VERSION "WUFR 23.1.0"

BS_: 1000000 : 0,0

BU_: FLSB DAQ FRSB RSB

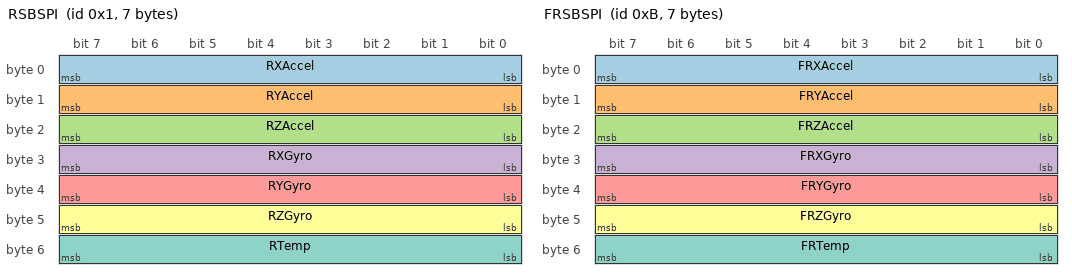
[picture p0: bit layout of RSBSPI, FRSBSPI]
BO_ 1 RSBSPI: 7 RSB
 SG_ RXAccel : 0|8@1- (0.307451,0.153725) [-39.2|39.2] "m/s^2" DAQ
 SG_ RYAccel : 8|8@1- (0.307451,0.153725) [-39.2|39.2] "m/s^2" DAQ
 SG_ RZAccel : 16|8@1- (0.307451,0.153725) [-39.2|39.2] "m/s^2" DAQ
 SG_ RXGyro : 24|8@1+ (1,0) [-80|80] "rad/s" DAQ
 SG_ RYGyro : 32|8@1+ (1,0) [-80|80] "rad/s" DAQ
 SG_ RZGyro : 40|8@1+ (1,0) [-80|80] "rad/s" DAQ
 SG_ RTemp : 48|8@1- (1,0) [-80|80] "rad/s" DAQ

BO_ 2 RSBAnlg1: 8 RSB
 SG_ RAnlg1 : 0|16@1+ (0.001,0) [0|5] "V" DAQ
 SG_ RAnlg2 : 16|32@1+ (0.001,0) [0|5] "V" DAQ
 SG_ RBrkPrs : 32|48@1+ (0.25,-125) [0|1000] "PSI" DAQ
 SG_ RAnlg4 : 48|64@1+ (0.001,0) [0|5] "V" DAQ

BO_ 3 RSBAnlg2: 4 RSB
 SG_ RAnlg5 : 0|16@1+ (0.001,0) [0|5] "V" DAQ
 SG_ RAnlg6 : 16|32@1+ (0.001,0) [0|5] "V" DAQ

BO_ 11 FRSBSPI: 7 FRSB
 SG_ FRXAccel : 0|8@1- (0.307451,0.153725) [-39.2|39.2] "m/s^2" DAQ
 SG_ FRYAccel : 8|8@1- (0.307451,0.153725) [-39.2|39.2] "m/s^2" DAQ
 SG_ FRZAccel : 16|8@1- (0.307451,0.153725) [-39.2|39.2] "m/s^2" DAQ
 SG_ FRXGyro : 24|8@1+ (1,0) [-80|80] "rad/s" DAQ
 SG_ FRYGyro : 32|8@1+ (1,0) [-80|80] "rad/s" DAQ
 SG_ FRZGyro : 40|8@1+ (1,0) [-80|80] "rad/s" DAQ
 SG_ FRTemp : 48|8@1- (1,0) [-80|80] "rad/s" DAQ

BO_ 12 FRSBAnlg1: 8 FRSB
 SG_ RadIn1 : 0|16@1+ (-0.13101462,375.7208) [-279.3523|375.7208] "F" DAQ
 SG_ RadIn2 : 16|32@1+ (-0.13101462,375.7208) [-279.3523|375.7208] "F" DAQ
 SG_ RadOut : 32|48@1+ (-0.13101462,375.7208) [-279.3523|375.7208] "F" DAQ
 SG_ FRAnlg4 : 48|64@1+ (0.001,0) [0|5] "V" DAQ

BO_ 13 FRSBAnlg2: 4 FRSB
 SG_ Pitot : 0|16@1+ (0.000045,-0.0225) [-0.0225|2.025] "PSI" DAQ
 SG_ FRAnlg6 : 16|32@1+ (0.001,0) [0|5] "V" DAQ

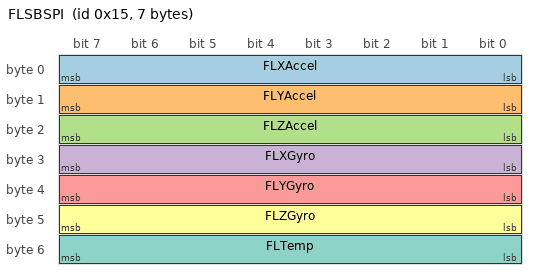
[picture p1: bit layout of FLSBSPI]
BO_ 21 FLSBSPI: 7 FLSB
 SG_ FLXAccel : 0|8@1- (0.307451,0.153725) [-39.2|39.2] "m/s^2" DAQ
 SG_ FLYAccel : 8|8@1- (0.307451,0.153725) [-39.2|39.2] "m/s^2" DAQ
 SG_ FLZAccel : 16|8@1- (0.307451,0.153725) [-39.2|39.2] "m/s^2" DAQ
 SG_ FLXGyro : 24|8@1+ (1,0) [-80|80] "rad/s" DAQ
 SG_ FLYGyro : 32|8@1+ (1,0) [-80|80] "rad/s" DAQ
 SG_ FLZGyro : 40|8@1+ (1,0) [-80|80] "rad/s" DAQ
 SG_ FLTemp : 48|8@1- (1,0) [-80|80] "rad/s" DAQ

BO_ 22 FLSBAnlg1: 8 FLSB
 SG_ FLAnlg1 : 0|16@1+ (0.001,0) [0|5] "V" DAQ
 SG_ FLAnlg2 : 16|32@1+ (0.001,0) [0|5] "V" DAQ
 SG_ FLAnlg3 : 32|48@1+ (0.001,0) [0|5] "V" DAQ
 SG_ FBrkPrs : 48|64@1+ (0.25,-125) [0|1000] "PSI" DAQ

BO_ 23 FLSBAnlg2: 4 FLSB
 SG_ FLAnlg5 : 0|16@1+ (0.001,0) [0|5] "V" DAQ
 SG_ FLAnlg6 : 16|32@1+ (0.001,0) [0|5] "V" DAQ

CM_ BU_ FLSB "Front left sensor board";
CM_ BU_ FRSB "Front right sensor board";
BA_DEF_DEF_  "GenMsgCycleTime" 100;
